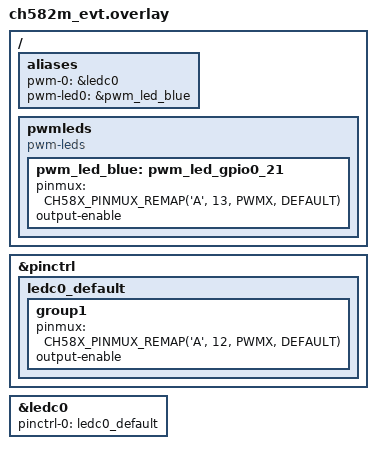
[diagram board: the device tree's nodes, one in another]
#include <zephyr/dt-bindings/pwm/pwm.h>

/ {
	aliases {
		pwm-0 = &ledc0;
		pwm-led0 = &pwm_led_blue;
	};

	pwmleds {
		compatible = "pwm-leds";
		pwm_led_blue: pwm_led_gpio0_21 {
			pinmux = <CH58X_PINMUX_REMAP('A', 13, PWMX, DEFAULT)>;
			output-enable;
			//label = "PWM LED0";
			//pwms = <&ledc0 0 1000 PWM_POLARITY_NORMAL>;
		};
	};
};

&pinctrl {
	ledc0_default: ledc0_default {
		group1 {
			pinmux = <CH58X_PINMUX_REMAP('A', 12, PWMX, DEFAULT)>;
			output-enable;
		};
	};
};

&ledc0 {
	pinctrl-0 = <&ledc0_default>;
	pinctrl-names = "default";
	status = "okay";

};
